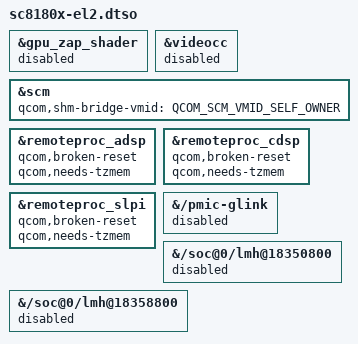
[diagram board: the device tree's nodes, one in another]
// SPDX-License-Identifier: BSD-3-Clause
#include <dt-bindings/firmware/qcom,scm.h>

/*
 * sc8180x specific modifications required to boot in EL2.
 *
 * This machine's firmware hands Linux over in EL1 because Qualcomm's
 * hypervisor (QHEE) owns EL2.  slbounce[1] can replace it through
 * Qualcomm's Secure-Launch flow, after which Linux runs in EL2 -- at the
 * cost of the hypervisor's services, so a few things have to be done
 * differently.  Everything below is only needed in EL2, which is why it
 * lives in an overlay instead of the SoC dtsi.
 *
 *  - The GPU zap shader cannot be authenticated without the hypervisor.
 *    Disabling the node makes the adreno driver program
 *    RBBM_SECVID_TRUST_CNTL itself (dmesg: "Zap shader not enabled - using
 *    SECVID_TRUST_CNTL instead"); keeping it disabled is also slbounce's
 *    precondition for switching to EL2 in the first place.
 *
 *  - The videocc is only used by venus, which is disabled on this board.
 *
 *  - The SHM bridge to the secure world has to be self-owned in EL2.  On
 *    sc8180x the bridge is blocklisted in EL1 ("hang in rmtfs memory
 *    assignment", drivers/firmware/qcom/qcom_tzmem.c), which is why the
 *    generic allocator is used there; QCOM_SCM_VMID_SELF_OWNER selects the
 *    EL2-correct variant instead.
 *
 *  - apps_smmu reports 127 context banks in its IDR1 register in EL2, while
 *    the device tree describes 106 context interrupts.  arm_smmu_device_probe()
 *    rejects that mismatch with -ENODEV ("found only 106 context irq(s) but
 *    127 required"), and every device with an iommus property then defers
 *    forever -- storage, USB, display, everything.  In EL1 this never
 *    surfaces because QHEE emulates the SMMU and reports only 106 banks.  The
 *    list below appends 21 placeholders, taken from SPI numbers that no node
 *    in this device tree uses, to satisfy the driver; they only affect fault
 *    reporting for banks 107..126.  TODO: replace them with the real 21
 *    interrupts once the vendor's IORT/ACPI data is available.
 *
 *  - The ADSP, CDSP and SLPI are started and owned by the firmware, and in
 *    EL2 the PAS reset sequence is not available: Linux can authenticate a
 *    firmware image (with qcom,needs-tzmem) but the remoteproc never leaves
 *    reset, so qcom_q6v5_wait_for_start() always times out with -ETIMEDOUT.
 *    "qcom,broken-reset" tells the remoteproc driver not to try starting them
 *    at all and to attach to whichever of them the boot firmware left
 *    running instead.  On probe the driver prints the SMP2P line state of all
 *    four interrupts per DSP, which is what tells us whether attaching is
 *    possible on this machine.
 *
 *  - pmic-glink needs the ADSP's rpmsg and LMH cannot set its thermal
 *    thresholds from EL2; both only produce errors there.
 *
 * [1] https://github.com/TravMurav/slbounce
 */

/dts-v1/;
/plugin/;

&gpu_zap_shader {
	status = "disabled";
};

&videocc {
	status = "disabled";
};

&scm {
	qcom,shm-bridge-vmid = <QCOM_SCM_VMID_SELF_OWNER>;
};


&remoteproc_adsp {
	qcom,broken-reset;
	qcom,needs-tzmem;
};

&remoteproc_cdsp {
	qcom,broken-reset;
	qcom,needs-tzmem;
};

&remoteproc_slpi {
	qcom,broken-reset;
	qcom,needs-tzmem;
};

&{/pmic-glink} {
	status = "disabled";
};

&{/soc@0/lmh@18350800} {
	status = "disabled";
};

&{/soc@0/lmh@18358800} {
	status = "disabled";
};
